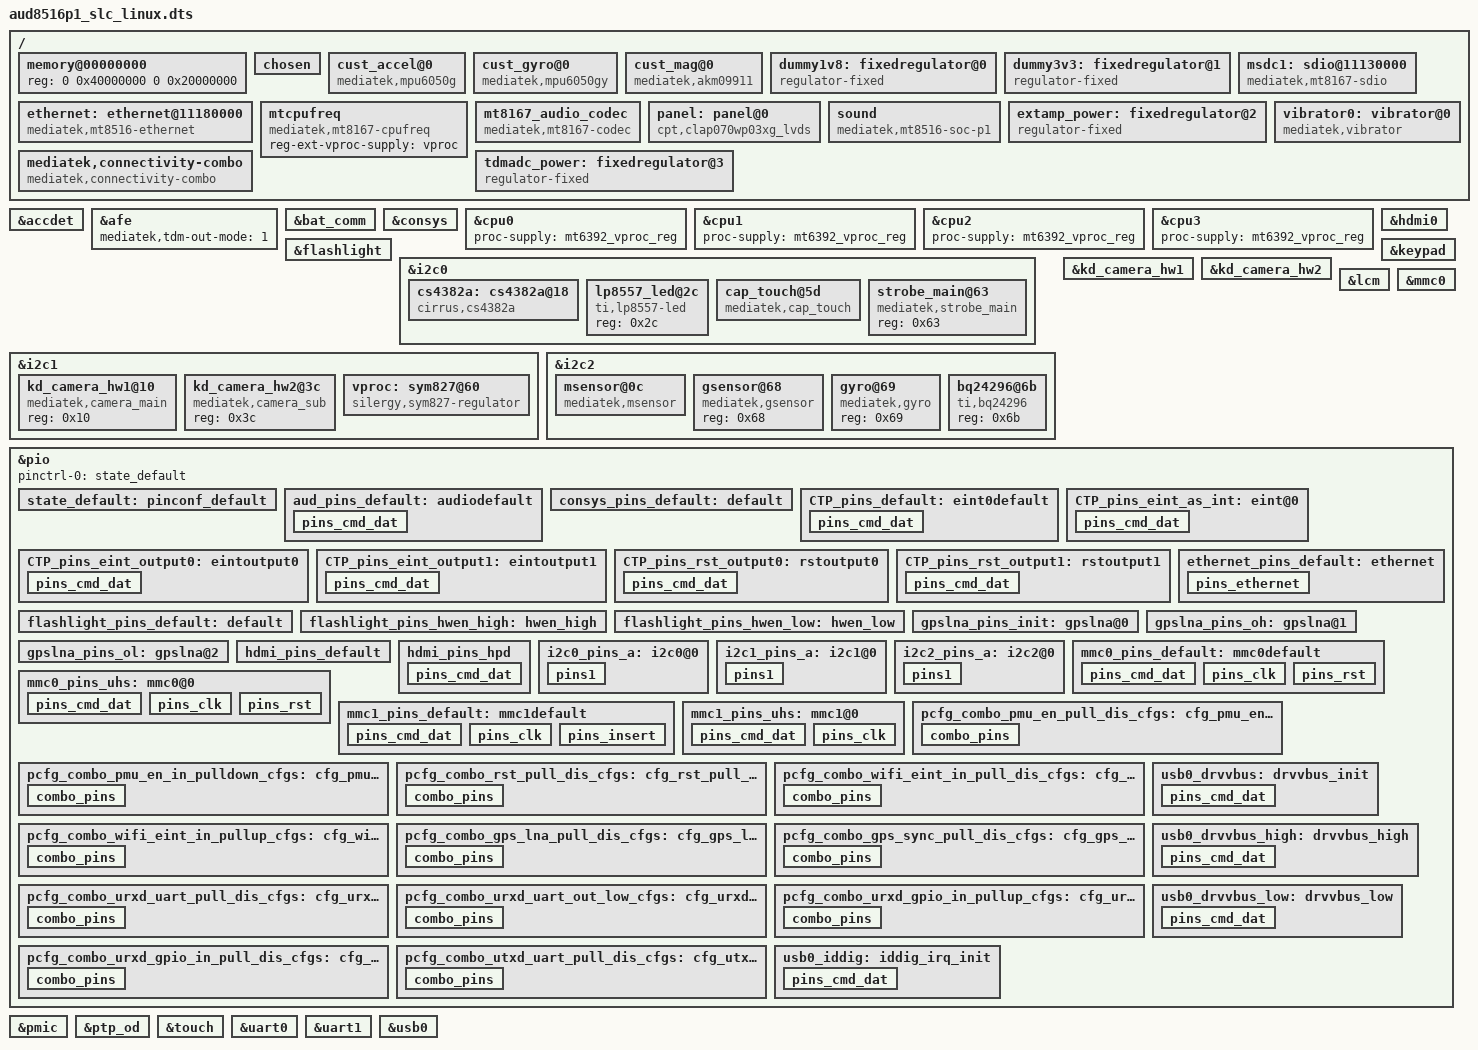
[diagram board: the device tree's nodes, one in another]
/*
 * Copyright (c) 2014-2015 MediaTek Inc.
 *
 * This program is free software; you can redistribute it and/or modify
 * it under the terms of the GNU General Public License version 2 as
 * published by the Free Software Foundation.
 *
 * This program is distributed in the hope that it will be useful,
 * MERCHANTABILITY or FITNESS FOR A PARTICULAR PURPOSE.  See the
 * GNU General Public License for more details.
 */

/dts-v1/;

#include "mt8167.dtsi"
#include "mt6392.dtsi"
#include "aud8516p1_linux_bat_setting.dtsi"

/ {
	memory@00000000 {
		device_type = "memory";
		reg = <0 0x40000000 0 0x20000000>;
	};

	/* chosen */
	chosen {
		bootargs = "console=ttyS0,921600n1 root=/dev/ram initrd=0x44000200,0x200000";
	};

/* sensor standardization */
	cust_accel@0 {
		compatible = "mediatek,mpu6050g";
		i2c_num	= <2>;
		i2c_addr = <0x68 0 0 0>;
		direction = <7>;
		power_id = <0xffff>;
		power_vol = <0>;
		firlen = <0>;
		is_batch_supported = <0>;
	};

	cust_gyro@0 {
		compatible = "mediatek,mpu6050gy";
		i2c_num = <2>;
		i2c_addr = <0x68 0 0 0>;
		direction = <7>;
		power_id = <0xffff>;
		power_vol = <0>;
		firlen = <0>;
		is_batch_supported = <0>;
	};

	cust_mag@0 {
		compatible = "mediatek,akm09911";
		i2c_num = <2>;
		i2c_addr = <0x0C 0 0 0>;
		direction = <6>;
		power_id = <0xffff>;
		power_vol = <0>;
		is_batch_supported			= <0>;
	};
/* sensor gpio standization */

	dummy1v8: fixedregulator@0 {
		compatible = "regulator-fixed";
		regulator-name = "mmc_io";
		regulator-min-microvolt = <1800000>;
		regulator-max-microvolt = <1800000>;
		regulator-always-on;
	};

	dummy3v3: fixedregulator@1 {
		compatible = "regulator-fixed";
		regulator-name = "mmc_power";
		regulator-min-microvolt = <3300000>;
		regulator-max-microvolt = <3300000>;
		regulator-always-on;
	};

	ethernet: ethernet@11180000 {
		compatible = "mediatek,mt8516-ethernet";
		reg = <0 0x11180000 0 0x1000>,
		      <0 0x10003400 0 0x1000>;
		interrupts = <GIC_SPI 111 IRQ_TYPE_LEVEL_LOW>;
		eth-gpios = <&pio 34 0>;
		clocks = <&topckgen CLK_TOP_RG_ETH>,
			 <&topckgen CLK_TOP_66M_ETH>,
			 <&topckgen CLK_TOP_133M_ETH>;
		clock-names = "core", "reg", "trans";
		eth-regulator-supply = <&mt6392_vmch_reg>;
		pinctrl-names = "default";
		pinctrl-0 = <&ethernet_pins_default>;
		status = "okay";
	};

	msdc1: sdio@11130000 {
		compatible = "mediatek,mt8167-sdio";
		reg = <0 0x11130000 0 0x1000>;
		interrupts = <GIC_SPI 79 IRQ_TYPE_LEVEL_LOW>;
		clocks = <&topckgen CLK_TOP_MSDC1>;
		clock-names = "sdio-clock";
		status = "disabled";
	};

	mtcpufreq {
		compatible = "mediatek,mt8167-cpufreq";
		reg-ext-vproc-supply = <&vproc>;
	};

	mt8167_audio_codec: mt8167_audio_codec {
		compatible = "mediatek,mt8167-codec";
		clocks = <&topckgen CLK_TOP_AUDIO>;
		clock-names = "bus";
		mediatek,afe-regmap = <&afe>;
		mediatek,apmixedsys-regmap = <&apmixedsys>;
		mediatek,pwrap-regmap = <&pwrap>;
		mediatek,speaker-mode = <0>; /* 0(CLASSD) 1(CLASSAB) */
		mediatek,dmic-wire-mode = <1>; /* 0(ONE_WIRE) 1(TWO_WIRE) */
	};

	panel: panel@0 {
		compatible = "cpt,clap070wp03xg_lvds";
		gpio_lcd_pwr = <&pio 67 0>;
		reg-lcm-supply = <&mt6392_vgp2_reg>;
	};

	sound: sound {
		compatible = "mediatek,mt8516-soc-p1";
		mediatek,platform = <&afe>;
		pinctrl-names = "default";
		pinctrl-0 = <&aud_pins_default>;
		extamp-supply = <&extamp_power>;
		tdmadc-supply = <&tdmadc_power>;
		cs4382a-rst-supply = <&mt6392_vmc_reg>;
		tdmadc-rst-gpio = <&pio 40 0>;
		mediatek,audio-codec = <&cs4382a>;
		status = "okay";
	};

	extamp_power: fixedregulator@2 {
		compatible = "regulator-fixed";
		regulator-name = "extamp_power";
		regulator-min-microvolt = <5000000>;
		regulator-max-microvolt = <5000000>;
		gpio = <&pio 51 0>;
		enable-active-high;
	};

	tdmadc_power: fixedregulator@3 {
		compatible = "regulator-fixed";
		regulator-name = "tdmadc_power";
		regulator-min-microvolt = <5000000>;
		regulator-max-microvolt = <5000000>;
		gpio = <&pio 50 0>;
		enable-active-high;
	};

	vibrator0:vibrator@0 {
		compatible = "mediatek,vibrator";
		vib_timer = <25>;
		vib_limit = <9>;
		vib_vol= <5>;
	};

	/* Connectivity */
	mediatek,connectivity-combo {
		compatible = "mediatek,connectivity-combo";
		gpio_combo_pmu_en_pin = <&pio 48 0>;	/* GPIO_COMBO_PMU_EN_PIN */
		gpio_combo_rst_pin = <&pio 18 0>;	/* GPIO_COMBO_RST_PIN pin */
		gpio_wifi_eint_pin = <&pio 20 0>;	/* GPIO_WIFI_EINT_PIN */
		gpio_gps_sync_pin = <&pio 4 0>;		/* GPIO_GPS_SYNC_PIN */
		gpio_gps_lna_pin = <&pio 3 0>;		/* GPIO_GPS_LNA_PIN */
		gpio_combo_urxd_pin = <&pio 64 0>;	/* GPIO_COMBO_URXD_PIN */
		gpio_combo_utxd_pin = <&pio 65 0>;	/* GPIO_COMBO_UTXD_PIN */
		pinctrl-names = "gpio_pmu_en_pull_dis",
			"gpio_pmu_en_in_pulldown",
			"gpio_rst_pull_dis",
			"gpio_wifi_eint_in_pull_dis",
			"gpio_wifi_eint_in_pullup",
			"gpio_gps_lna_pull_dis",
			"gpio_gps_sync_pull_dis",
			"gpio_urxd_uart_pull_dis",
			"gpio_urxd_gpio_in_pullup",
			"gpio_urxd_uart_out_low",
			"gpio_urxd_gpio_in_pull_dis",
			"gpio_utxd_uart_pull_dis";
		pinctrl-0 = <&pcfg_combo_pmu_en_pull_dis_cfgs>;
		pinctrl-1 = <&pcfg_combo_pmu_en_in_pulldown_cfgs>;
		pinctrl-2 = <&pcfg_combo_rst_pull_dis_cfgs>;
		pinctrl-3 = <&pcfg_combo_wifi_eint_in_pull_dis_cfgs>;
		pinctrl-4 = <&pcfg_combo_wifi_eint_in_pullup_cfgs>;
		pinctrl-5 = <&pcfg_combo_gps_lna_pull_dis_cfgs>;
		pinctrl-6 = <&pcfg_combo_gps_sync_pull_dis_cfgs>;
		pinctrl-7 = <&pcfg_combo_urxd_uart_pull_dis_cfgs>;
		pinctrl-8 = <&pcfg_combo_urxd_gpio_in_pullup_cfgs>;
		pinctrl-9 = <&pcfg_combo_urxd_uart_out_low_cfgs>;
		pinctrl-10 = <&pcfg_combo_urxd_gpio_in_pull_dis_cfgs>;
		pinctrl-11 = <&pcfg_combo_utxd_uart_pull_dis_cfgs>;
		interrupt-parent = <&pio>;
		interrupts = < 20 IRQ_TYPE_LEVEL_LOW >;	/* WIFI EINT num is 1 active low level-sensitive */
		status = "okay";
	};
};

&accdet {
	interrupts-extended = <&sysirq GIC_SPI 152 IRQ_TYPE_LEVEL_LOW>,
			<&pio 16 IRQ_TYPE_LEVEL_HIGH>;
	eint-debounce = <256000>;
	accdet-gpio = <&pio 16 0>;
	accdet-mic-vol = <7>;
	headset-mode-setting = <0x500 0x500 1 0x1f0 0x800 0x800 0x20>;
	accdet-plugout-debounce = <20>;
	/*1:ACC mode, 2:low cost without in bias, 6:low cost with in bias*/
	accdet-mic-mode = <1>;
	/*0--MD_MAX--UP_MAX--DW_MAX*/
	headset-three-key-threshold = <0 80 220 500>;
	/*0--MD_MAX--VOICE_MAX--UP_MAX--DW_MAX*/
	headset-four-key-threshold = <0 58 121 192 450>;
	status = "okay";
};

&afe {
	/* 0(HDMI) 1(I2S) 2(TDM) */
	mediatek,tdm-out-mode = <1>;
};

&bat_comm {
	interrupt-parent = <&pmic>;
	interrupts = <10 IRQ_TYPE_LEVEL_HIGH>;
};

&consys {
	pinctrl-names = "default", "gps_lna_state_init", "gps_lna_state_oh", "gps_lna_state_ol";
	pinctrl-0 = <&consys_pins_default>;
	pinctrl-1 = <&gpslna_pins_init>;
	pinctrl-2 = <&gpslna_pins_oh>;
	pinctrl-3 = <&gpslna_pins_ol>;
	vcn18-supply = <&mt6392_vcn18_reg>;
	vcn35-supply = <&mt6392_vcn35_reg>;
	status = "okay";
};

&cpu0 {
	proc-supply = <&mt6392_vproc_reg>;
};

&cpu1 {
	proc-supply = <&mt6392_vproc_reg>;
};

&cpu2 {
	proc-supply = <&mt6392_vproc_reg>;
};

&cpu3 {
	proc-supply = <&mt6392_vproc_reg>;
};

&flashlight {
	pinctrl-names = "default", "hwen_high", "hwen_low";
	pinctrl-0 = <&flashlight_pins_default>;
	pinctrl-1 = <&flashlight_pins_hwen_high>;
	pinctrl-2 = <&flashlight_pins_hwen_low>;
	status = "okay";
};

&hdmi0 {
	pinctrl-names = "default", "hdmi_hpd";
	pinctrl-0 = <&hdmi_pins_default>;
	pinctrl-1 = <&hdmi_pins_hpd>;
	status = "okay";
};

&i2c0 {
	clock-div = <2>;
	pinctrl-names = "default";
	pinctrl-0 = <&i2c0_pins_a>;
	status = "okay";

	cs4382a: cs4382a@18 {
		compatible = "cirrus,cs4382a";
		reg = <0x18>;
		rst-gpio = <&pio 24 0>;
		cs4382a-supply = <&mt6392_vcamaf_reg>;
	};

	lp8557_led@2c {
		compatible = "ti,lp8557-led";
		reg = <0x2c>;
	};

	cap_touch@5d {
		compatible = "mediatek,cap_touch";
		reg = <0x5d>;
		interrupt-parent = <&pio>;
		interrupts = <19 IRQ_TYPE_EDGE_FALLING>;
		int-gpio = <&pio 19 0>;
		rst-gpio = <&pio 18 0>;
	};

	strobe_main@63 {
		compatible = "mediatek,strobe_main";
		reg = <0x63>;
	};
};

&i2c1 {
	clock-div = <2>;
	pinctrl-names = "default";
	pinctrl-0 = <&i2c1_pins_a>;
	status = "okay";

	kd_camera_hw1@10 {
		compatible = "mediatek,camera_main";
		reg = <0x10>;
	};

	kd_camera_hw2@3c {
		compatible = "mediatek,camera_sub";
		reg = <0x3c>;
	};

	vproc: sym827@60 {
		compatible = "silergy,sym827-regulator";
		reg = <0x60>;
		regulator-name = "vproc";
		regulator-min-microvolt = <600000>;
		regulator-max-microvolt = <1387500>;
		regulator-enable-ramp-delay = <400>;
		regulator-ramp-delay = <8333>;
		regulator-always-on;
		vsel-gpio = <&pio 34 0>;
	};
};

&i2c2 {
	clock-div = <2>;
	pinctrl-names = "default";
	pinctrl-0 = <&i2c2_pins_a>;
	status = "okay";

	msensor@0c {
		compatible = "mediatek,msensor";
		reg = <0x0c>;
		rst-gpio = <&pio 52 0>;
	};

	gsensor@68 {
		compatible = "mediatek,gsensor";
		reg = <0x68>;
	};

	gyro@69 {
		compatible = "mediatek,gyro";
		reg = <0x69>;
	};

	bq24296@6b {
		compatible = "ti,bq24296";
		reg = <0x6b>;
	};
};

/* Main Cam */
&kd_camera_hw1 {
	reg-vcama-supply = <&mt6392_vcama_reg>;		/* AVDD */
	reg-vcamd-supply = <&mt6392_vcamd_reg>;		/* DVDD */
	reg-vcamio-supply = <&mt6392_vcamio_reg>;	/* DOVDD */
	reg-vcamaf-supply = <&mt6392_vcamaf_reg>;	/* AFVDD */
	status = "okay";
};

/* Sub Cam */
/* Same power pins as Main, actually, it can be commented */
&kd_camera_hw2{
	reg-vcama-supply = <&mt6392_vcama_reg>;		/* AVDD */
	reg-vcamd-supply = <&mt6392_vcamd_reg>;		/* DVDD */
	reg-vcamio-supply = <&mt6392_vcamio_reg>;	/* DOVDD */
	reg-vcamaf-supply = <&mt6392_vcamaf_reg>;	/* AFVDD */
};

&keypad {
	mediatek,kpd-key-debounce = <1024>;
	mediatek,kpd-sw-pwrkey = <116>;
	mediatek,kpd-hw-pwrkey = <8>;
	mediatek,kpd-sw-rstkey  = <114>;
	mediatek,kpd-hw-rstkey = <17>;
	mediatek,kpd-use-extend-type = <0>;
	/*HW Keycode [0~71] -> Linux Keycode*/
	mediatek,kpd-hw-map-num = <72>;
	mediatek,kpd-hw-init-map = <115 113 0 0 0 0 0 0 0 0 0 0 0 0 0 0 0 0 0 0 0 0 0 0
			0 0 0 0 0 0 0 0 0 0 0 0 0 0 0 0 0 0 0 0 0 0 0 0
			0 0 0 0 0 0 0 0 0 0 0 0 0 0 0 0 0 0 0 0 0 0 0 0 >;
	mediatek,kpd-pwrkey-eint-gpio = <0>;
	mediatek,kpd-pwkey-gpio-din  = <0>;
	mediatek,kpd-hw-dl-key0 = <0>;
	mediatek,kpd-hw-dl-key1 = <17>;
	mediatek,kpd-hw-dl-key2 = <8>;
	mediatek,kpd-hw-recovery-key = <17>;
	mediatek,kpd-hw-factory-key  = <0>;
};

&lcm {
	gpio_lcd_pwr = <&pio 67 0>;
	reg-lcm-supply = <&mt6392_vgp2_reg>;
};

&mmc0 {
	pinctrl-names = "default", "state_uhs";
	pinctrl-0 = <&mmc0_pins_default>;
	pinctrl-1 = <&mmc0_pins_uhs>;
	status = "okay";
	bus-width = <8>;
	max-frequency = <200000000>;
	cap-mmc-highspeed;
	mmc-hs200-1_8v;
	cap-mmc-hw-reset;
	vmmc-supply = <&mt6392_vemc3v3_reg>;
	vqmmc-supply = <&mt6392_vio18_reg>;
	non-removable;
};

&msdc1 {
	pinctrl-names = "default", "state_uhs";
	pinctrl-0 = <&mmc1_pins_default>;
	pinctrl-1 = <&mmc1_pins_uhs>;
	status = "okay";
	clk_src = <2>;  /*<MSDC30_CLKSRC_200MHZ>*/
	host_function = <2>;
	bus-width = <4>;
	max-frequency = <200000000>;
	cap-sd-highspeed;
	sd-uhs-sdr50;
	sd-uhs-sdr104;
	vmmc-supply = <&mt6392_vmch_reg>;
	vqmmc-supply = <&mt6392_vmc_reg>;
};

&pio {
	pinctrl-names = "default";
	pinctrl-0 = <&state_default>;

	state_default:pinconf_default {
	};

	aud_pins_default: audiodefault {
		pins_cmd_dat {
			pinmux = <MT8167_PIN_25_EINT25__FUNC_I2S_8CH_MCK>,
				 <MT8167_PIN_68_MSDC2_CMD__FUNC_I2S_8CH_DO4>,
				 <MT8167_PIN_69_MSDC2_CLK__FUNC_I2S_8CH_DO3>,
				 <MT8167_PIN_70_MSDC2_DAT0__FUNC_I2S_8CH_DO2>,
				 <MT8167_PIN_71_MSDC2_DAT1__FUNC_I2S_8CH_DO1>,
				 <MT8167_PIN_72_MSDC2_DAT2__FUNC_I2S_8CH_LRCK>,
				 <MT8167_PIN_73_MSDC2_DAT3__FUNC_I2S_8CH_BCK>,
				 <MT8167_PIN_100_CMDAT0__FUNC_TDM_RX_MCK>,
				 <MT8167_PIN_101_CMDAT1__FUNC_TDM_RX_BCK>,
				 <MT8167_PIN_102_CMMCLK__FUNC_TDM_RX_LRCK>,
				 <MT8167_PIN_103_CMPCLK__FUNC_TDM_RX_DI>,
				 <MT8167_PIN_55_I2S_DATA_IN__FUNC_I2S0_DI>,
				 <MT8167_PIN_56_I2S_LRCK__FUNC_I2S0_LRCK>,
				 <MT8167_PIN_57_I2S_BCK__FUNC_I2S0_BCK>,
				 <MT8167_PIN_66_LCM_RST__FUNC_I2S0_MCK>;
		};
	};

	/* CONSYS GPIO Settings - Start */
	consys_pins_default: default {

	};
	/* CONSYS GPIO Settings - End */

	CTP_pins_default: eint0default {
		pins_cmd_dat {
			pins = <MT8167_PIN_19_EINT19__FUNC_GPIO19>;
			slew-rate = <0>;
			bias-disable;
		};
	};

	CTP_pins_eint_as_int: eint@0 {
		pins_cmd_dat {
			pins = <MT8167_PIN_19_EINT19__FUNC_GPIO19>;
			slew-rate = <0>;
			bias-disable;
		};
	};

	CTP_pins_eint_output0: eintoutput0 {
		pins_cmd_dat {
			pins = <MT8167_PIN_19_EINT19__FUNC_GPIO19>;
			slew-rate = <1>;
			output-low;
		};
	};

	CTP_pins_eint_output1: eintoutput1 {
		pins_cmd_dat {
			pins = <MT8167_PIN_19_EINT19__FUNC_GPIO19>;
			slew-rate = <1>;
			output-high;
		};
	};

	CTP_pins_rst_output0: rstoutput0 {
		pins_cmd_dat {
			pins = <MT8167_PIN_18_EINT18__FUNC_GPIO18>;
			slew-rate = <1>;
			output-low;
		};
	};

	CTP_pins_rst_output1: rstoutput1 {
		pins_cmd_dat {
			pins = <MT8167_PIN_18_EINT18__FUNC_GPIO18>;
			slew-rate = <1>;
			output-high;
		};
	};

	ethernet_pins_default: ethernet {
		pins_ethernet {
			pinmux = <MT8167_PIN_0_EINT0__FUNC_EXT_TXD0>,
				 <MT8167_PIN_1_EINT1__FUNC_EXT_TXD1>,
				 <MT8167_PIN_2_EINT2__FUNC_EXT_TXD2>,
				 <MT8167_PIN_3_EINT3__FUNC_EXT_TXD3>,
				 <MT8167_PIN_4_EINT4__FUNC_EXT_TXC>,
				 <MT8167_PIN_5_EINT5__FUNC_EXT_RXER>,
				 <MT8167_PIN_6_EINT6__FUNC_EXT_RXC>,
				 <MT8167_PIN_7_EINT7__FUNC_EXT_RXDV>,
				 <MT8167_PIN_8_EINT8__FUNC_EXT_RXD0>,
				 <MT8167_PIN_9_EINT9__FUNC_EXT_RXD1>,
				 <MT8167_PIN_10_EINT10__FUNC_EXT_RXD2>,
				 <MT8167_PIN_11_EINT11__FUNC_EXT_RXD3>,
				 <MT8167_PIN_12_EINT12__FUNC_EXT_TXEN>,
				 <MT8167_PIN_37_MRG_SYNC__FUNC_EXT_COL>,
				 <MT8167_PIN_38_MRG_DI__FUNC_EXT_MDIO>,
				 <MT8167_PIN_39_MRG_DO__FUNC_EXT_MDC>;
		};
	};

	flashlight_pins_default: default {
	};

	flashlight_pins_hwen_high: hwen_high {
	};

	flashlight_pins_hwen_low: hwen_low {
	};

	/* CONSYS GPIO Settings - Start */
	gpslna_pins_init: gpslna@0 {
	};

	gpslna_pins_oh: gpslna@1 {
	};

	gpslna_pins_ol: gpslna@2 {
	};
	/* CONSYS GPIO Settings - End */

	hdmi_pins_default: hdmi_pins_default {
	};

	hdmi_pins_hpd: hdmi_pins_hpd {
		pins_cmd_dat {
			pins = <MT8167_PIN_122_HTPLG__FUNC_HTPLG>;
			slew-rate = <0>;
			bias-pull-down;
		};
	};

	i2c0_pins_a: i2c0@0 {
		pins1 {
			pinmux = <MT8167_PIN_58_SDA0__FUNC_SDA0_0>,
				 <MT8167_PIN_59_SCL0__FUNC_SCL0_0>;
			bias-disable;
		};
	};

	i2c1_pins_a: i2c1@0 {
		pins1 {
			pinmux = <MT8167_PIN_52_SDA1__FUNC_SDA1_0>,
				 <MT8167_PIN_53_SCL1__FUNC_SCL1_0>;
			bias-disable;
		};
	};

	i2c2_pins_a: i2c2@0 {
		pins1 {
			pinmux = <MT8167_PIN_60_SDA2__FUNC_SDA2_0>,
				 <MT8167_PIN_61_SCL2__FUNC_SCL2_0>;
			bias-disable;
		};
	};

	mmc0_pins_default: mmc0default {
		pins_cmd_dat {
			pinmux = <MT8167_PIN_120_MSDC0_DAT0__FUNC_MSDC0_DAT0>,
				<MT8167_PIN_119_MSDC0_DAT1__FUNC_MSDC0_DAT1>,
				<MT8167_PIN_118_MSDC0_DAT2__FUNC_MSDC0_DAT2>,
				<MT8167_PIN_117_MSDC0_DAT3__FUNC_MSDC0_DAT3>,
				<MT8167_PIN_113_MSDC0_DAT4__FUNC_MSDC0_DAT4>,
				<MT8167_PIN_112_MSDC0_DAT5__FUNC_MSDC0_DAT5>,
				<MT8167_PIN_111_MSDC0_DAT6__FUNC_MSDC0_DAT6>,
				<MT8167_PIN_110_MSDC0_DAT7__FUNC_MSDC0_DAT7>,
				<MT8167_PIN_115_MSDC0_CMD__FUNC_MSDC0_CMD>;
			input-enable;
			bias-pull-up;
		};

		pins_clk {
			pinmux = <MT8167_PIN_116_MSDC0_CLK__FUNC_MSDC0_CLK>;
			bias-pull-down;
		};

		pins_rst {
			pinmux = <MT8167_PIN_114_MSDC0_RSTB__FUNC_MSDC0_RSTB>;
			bias-pull-up;
		};
	};

	mmc0_pins_uhs: mmc0@0{
		pins_cmd_dat {
			pinmux = <MT8167_PIN_120_MSDC0_DAT0__FUNC_MSDC0_DAT0>,
				<MT8167_PIN_119_MSDC0_DAT1__FUNC_MSDC0_DAT1>,
				<MT8167_PIN_118_MSDC0_DAT2__FUNC_MSDC0_DAT2>,
				<MT8167_PIN_117_MSDC0_DAT3__FUNC_MSDC0_DAT3>,
				<MT8167_PIN_113_MSDC0_DAT4__FUNC_MSDC0_DAT4>,
				<MT8167_PIN_112_MSDC0_DAT5__FUNC_MSDC0_DAT5>,
				<MT8167_PIN_111_MSDC0_DAT6__FUNC_MSDC0_DAT6>,
				<MT8167_PIN_110_MSDC0_DAT7__FUNC_MSDC0_DAT7>,
				<MT8167_PIN_115_MSDC0_CMD__FUNC_MSDC0_CMD>;
			input-enable;
			drive-strength = <MTK_DRIVE_6mA>;
			bias-pull-up = <MTK_PUPD_SET_R1R0_01>;
		};

		pins_clk {
			pinmux = <MT8167_PIN_116_MSDC0_CLK__FUNC_MSDC0_CLK>;
			drive-strength = <MTK_DRIVE_8mA>;
			bias-pull-down = <MTK_PUPD_SET_R1R0_10>;
		};

		pins_rst {
			pinmux = <MT8167_PIN_114_MSDC0_RSTB__FUNC_MSDC0_RSTB>;
			bias-pull-up;
		};
	};

	mmc1_pins_default: mmc1default {
		pins_cmd_dat {
			pinmux = <MT8167_PIN_106_MSDC1_DAT0__FUNC_MSDC1_DAT0>,
				<MT8167_PIN_107_MSDC1_DAT1__FUNC_MSDC1_DAT1>,
				<MT8167_PIN_108_MSDC1_DAT2__FUNC_MSDC1_DAT2>,
				<MT8167_PIN_109_MSDC1_DAT3__FUNC_MSDC1_DAT3>,
				<MT8167_PIN_104_MSDC1_CMD__FUNC_MSDC1_CMD>;
			input-enable;
			drive-strength = <MTK_DRIVE_6mA>;
			bias-pull-up = <MTK_PUPD_SET_R1R0_01>;
		};

		pins_clk {
			pinmux = <MT8167_PIN_105_MSDC1_CLK__FUNC_MSDC1_CLK>;
			drive-strength = <MTK_DRIVE_6mA>;
			bias-pull-down = <MTK_PUPD_SET_R1R0_10>;
		};

		pins_insert {
			pinmux = <MT8167_PIN_14_EINT14__FUNC_GPIO14>;
			bias-pull-up;
		};
	};

	mmc1_pins_uhs: mmc1@0 {
		pins_cmd_dat {
			pinmux = <MT8167_PIN_106_MSDC1_DAT0__FUNC_MSDC1_DAT0>,
				<MT8167_PIN_107_MSDC1_DAT1__FUNC_MSDC1_DAT1>,
				<MT8167_PIN_108_MSDC1_DAT2__FUNC_MSDC1_DAT2>,
				<MT8167_PIN_109_MSDC1_DAT3__FUNC_MSDC1_DAT3>,
				<MT8167_PIN_104_MSDC1_CMD__FUNC_MSDC1_CMD>;
			input-enable;
			drive-strength = <MTK_DRIVE_6mA>;
			bias-pull-up = <MTK_PUPD_SET_R1R0_01>;
		};

		pins_clk {
			pinmux = <MT8167_PIN_105_MSDC1_CLK__FUNC_MSDC1_CLK>;
			drive-strength = <MTK_DRIVE_8mA>;
			bias-pull-down = <MTK_PUPD_SET_R1R0_10>;
		};
	};

/* Connectivity GPIO start */
	pcfg_combo_pmu_en_pull_dis_cfgs:cfg_pmu_en_pull_dis {
		combo_pins {
			pins = <MT8167_PIN_48_SPI_CS__FUNC_GPIO48>;
			bias-disable;
		};
	};

	pcfg_combo_pmu_en_in_pulldown_cfgs:cfg_pmu_en_in_pulldown {
		combo_pins {
			pins = <MT8167_PIN_48_SPI_CS__FUNC_GPIO48>;
			bias-pull-down;
		};
	};

	pcfg_combo_rst_pull_dis_cfgs:cfg_rst_pull_dis {
		combo_pins {
			pins = <MT8167_PIN_18_EINT18__FUNC_GPIO18>;
			bias-disable;
		};
	};

	pcfg_combo_wifi_eint_in_pull_dis_cfgs:cfg_wifi_eint_in_pull_dis {
		combo_pins {
			pins = <MT8167_PIN_20_EINT20__FUNC_GPIO20>;
			slew-rate = <0>;
			bias-disable;
		};
	};

	pcfg_combo_wifi_eint_in_pullup_cfgs:cfg_wifi_eint_in_pullup {
		combo_pins {
			pins = <MT8167_PIN_20_EINT20__FUNC_GPIO20>;
			slew-rate = <0>;
			bias-pull-up = <00>;
		};
	};

	pcfg_combo_gps_lna_pull_dis_cfgs:cfg_gps_lna_pull_dis {
		combo_pins {
			pins = <MT8167_PIN_3_EINT3__FUNC_GPIO3>;
			bias-disable;
		};
	};

	pcfg_combo_gps_sync_pull_dis_cfgs:cfg_gps_sync_pull_dis {
		combo_pins {
			pins = <MT8167_PIN_4_EINT4__FUNC_GPIO4>;
			bias-disable;
		};
	};

	pcfg_combo_urxd_uart_pull_dis_cfgs:cfg_urxd_pull_dis {
		combo_pins {
			pinmux = <MT8167_PIN_64_URXD1__FUNC_URXD1>;
			bias-disable;
		};
	};

	pcfg_combo_urxd_uart_out_low_cfgs:cfg_urxd_out_low {
		combo_pins {
			pinmux = <MT8167_PIN_64_URXD1__FUNC_GPIO64>;
			slew-rate = <1>;
			output-low;
		};
	};

	pcfg_combo_urxd_gpio_in_pullup_cfgs:cfg_urxd_in_pullup {
		combo_pins {
			pinmux = <MT8167_PIN_64_URXD1__FUNC_URXD1>;
			input-enable;
			bias-pull-up;
		};
	};

	pcfg_combo_urxd_gpio_in_pull_dis_cfgs:cfg_urxd_in_pull_dis {
		combo_pins {
			pinmux = <MT8167_PIN_64_URXD1__FUNC_URXD1>;
			input-enable;
			bias-disable;
		};
	};

	pcfg_combo_utxd_uart_pull_dis_cfgs:cfg_utxd_pull_dis {
		combo_pins {
			pinmux = <MT8167_PIN_65_UTXD1__FUNC_UTXD1>;
			bias-disable;
		};
	};
/* Connectivity GPIO end */

/* USB GPIO start */
	usb0_drvvbus: drvvbus_init {
		pins_cmd_dat {
			pins = <MT8167_PIN_49_SPI_CK__FUNC_GPIO49>;
			output-low;
		};
	};

	usb0_drvvbus_high: drvvbus_high {
		pins_cmd_dat {
			pins = <MT8167_PIN_49_SPI_CK__FUNC_GPIO49>;
			slew-rate = <1>;
			output-high;
		};
	};

	usb0_drvvbus_low: drvvbus_low {
		pins_cmd_dat {
			pins = <MT8167_PIN_49_SPI_CK__FUNC_GPIO49>;
			slew-rate = <1>;
			output-low;
		};
	};

	usb0_iddig: iddig_irq_init {
		pins_cmd_dat {
			pins = <MT8167_PIN_41_KPROW1__FUNC_IDDIG>;
			slew-rate = <0>;
			bias-pull-up = <00>;
		};
	};
/* USB GPIO end */
};

&pmic {
	interrupt-parent = <&pio>;
	interrupts = <28 IRQ_TYPE_LEVEL_HIGH>;
	interrupt-controller;
	#interrupt-cells = <2>;
};

&ptp_od {
	vproc-supply = <&mt6392_vproc_reg>;
	vcore-supply = <&mt6392_vcore_reg>;
};

&touch {
	vtouch-supply = <&mt6392_vgp1_reg>;
	tpd-resolution = <800 1280>;
	use-tpd-button = <0>;
	tpd-key-num = <4>;
	tpd-key-local= <139 172 158 0>;
	tpd-key-dim-local = <60 850 50 30 180 850 50 30 300 850 50 30 420 850 50 30>;
	tpd-max-touch-num = <5>;
	tpd-filter-enable = <1>;
	tpd-filter-pixel-density = <124>;
	tpd-filter-custom-prameters = <0 0 0 0 0 0 0 0 0 0 0 0>;
	tpd-filter-custom-speed = <0 0 0>;
	pinctrl-names = "default", "state_eint_as_int", "state_eint_output0", "state_eint_output1",
		"state_rst_output0", "state_rst_output1";
	pinctrl-0 = <&CTP_pins_default>;
	pinctrl-1 = <&CTP_pins_eint_as_int>;
	pinctrl-2 = <&CTP_pins_eint_output0>;
	pinctrl-3 = <&CTP_pins_eint_output1>;
	pinctrl-4 = <&CTP_pins_rst_output0>;
	pinctrl-5 = <&CTP_pins_rst_output1>;
	status = "okay";
};

&uart0 {
	status="okay";
};

&uart1 {
	status="okay";
};

&usb0 {
	pinctrl-names = "iddig_irq_init", "drvvbus_init", "drvvbus_low", "drvvbus_high";
	pinctrl-0 = <&usb0_iddig>;
	pinctrl-1 = <&usb0_drvvbus>;
	pinctrl-2 = <&usb0_drvvbus_low>;
	pinctrl-3 = <&usb0_drvvbus_high>;
	status = "okay";
	drvvbus_gpio = <&pio 49 2>;
};
